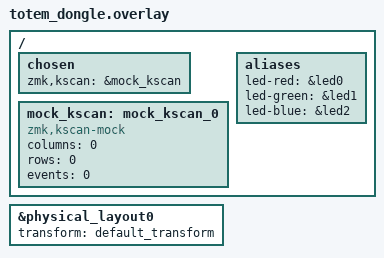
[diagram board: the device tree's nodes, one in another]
#include "totem.dtsi"

/ {
    chosen {
        zmk,kscan = &mock_kscan;
    };

    mock_kscan: mock_kscan_0 {
        compatible = "zmk,kscan-mock";
        columns = <0>;
        rows = <0>;
        events = <0>;
    };

    aliases {
        led-red = &led0;
        led-green = &led1;
        led-blue = &led2;
    };
};

&physical_layout0 {
    transform = <&default_transform>;
};
